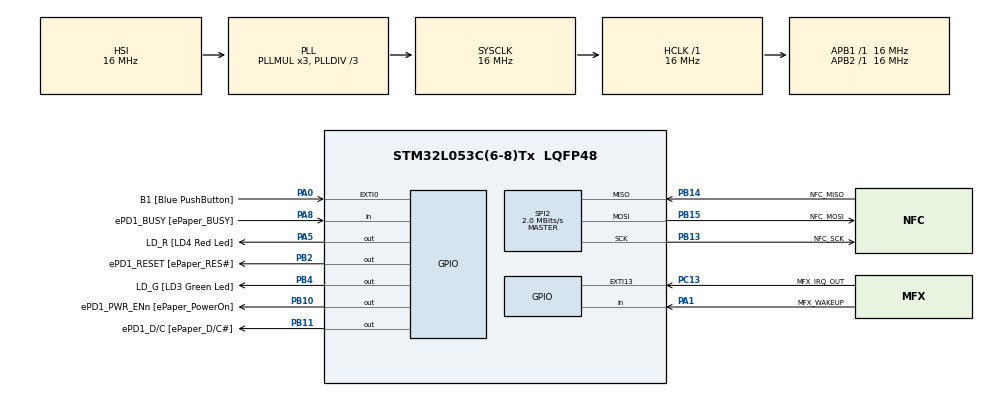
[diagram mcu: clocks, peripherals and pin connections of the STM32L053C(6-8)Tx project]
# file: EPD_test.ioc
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Mcu.Family=STM32L0
Mcu.Name=STM32L053C(6-8)Tx
Mcu.Package=LQFP48
PA0.GPIO_Label=B1 [Blue PushButton]
PA0.GPIO_ModeDefaultEXTI=GPIO_MODE_EVT_RISING
PA0.GPIO_PuPd=GPIO_NOPULL
PA0.Signal=GPXTI0
PA1.GPIO_Label=MFX_WAKEUP
PA1.Signal=GPIO_Input
PA10.GPIO_Label=USART_RX
PA10.Signal=USART1_RX
PA11.GPIO_Label=USB1_DM
PA11.Signal=USB_DM
PA12.GPIO_Label=USB1_DP
PA12.Signal=USB_DP
PA13.GPIO_Label=SWDIO
PA13.Signal=SYS_SWDIO
PA15.GPIO_Label=ePD1_CS [ePaper_CS\#]
PA15.GPIO_Mode=GPIO_MODE_AF_PP
PA15.GPIO_PuPd=GPIO_NOPULL
PA15.GPIO_Speed=GPIO_SPEED_FREQ_LOW
PA15.Signal=SPI1_NSS
PA2.Signal=TSC_G1_IO3
PA3.Signal=TSC_G1_IO4
PA5.GPIO_Label=LD_R [LD4 Red Led]
PA5.GPIO_ModeDefaultOutputPP=GPIO_MODE_OUTPUT_PP
PA5.GPIO_PuPd=GPIO_NOPULL
PA5.GPIO_Speed=GPIO_SPEED_FREQ_LOW
PA5.Signal=GPIO_Output
PA6.Signal=TSC_G2_IO3
PA7.Signal=TSC_G2_IO4
PA8.GPIO_Label=ePD1_BUSY [ePaper_BUSY]
PA8.GPIO_Mode=GPIO_MODE_INPUT
PA8.GPIO_PuPd=GPIO_NOPULL
PA8.Signal=GPIO_Input
PA9.GPIO_Label=USART_TX
PA9.Signal=USART1_TX
PB0.Signal=TSC_G3_IO2
PB1.Signal=TSC_G3_IO3
PB10.GPIO_Label=ePD1_PWR_ENn [ePaper_PowerOn]
PB10.GPIO_ModeDefaultOutputPP=GPIO_MODE_OUTPUT_PP
PB10.GPIO_PuPd=GPIO_NOPULL
PB10.GPIO_Speed=GPIO_SPEED_FREQ_LOW
PB10.Signal=GPIO_Output
PB11.GPIO_Label=ePD1_D/C [ePaper_D/C\#]
PB11.GPIO_ModeDefaultOutputPP=GPIO_MODE_OUTPUT_PP
PB11.GPIO_PuPd=GPIO_NOPULL
PB11.GPIO_Speed=GPIO_SPEED_FREQ_LOW
PB11.Signal=GPIO_Output
PB12.GPIO_Label=NFC_NSS
PB12.Signal=SPI2_NSS
PB13.GPIO_Label=NFC_SCK
PB13.Mode=Full_Duplex_Master
PB13.Signal=SPI2_SCK
PB14.GPIO_Label=NFC_MISO
PB14.Mode=Full_Duplex_Master
PB14.Signal=SPI2_MISO
PB15.GPIO_Label=NFC_MOSI
PB15.Mode=Full_Duplex_Master
PB15.Signal=SPI2_MOSI
PB2.GPIO_Label=ePD1_RESET [ePaper_RES\#]
PB2.GPIO_ModeDefaultOutputPP=GPIO_MODE_OUTPUT_PP
PB2.GPIO_PuPd=GPIO_NOPULL
PB2.GPIO_Speed=GPIO_SPEED_FREQ_LOW
PB2.Signal=GPIO_Output
PB3.GPIO_Label=ePD1_SCK [ePaper_SCK]
PB3.GPIO_Mode=GPIO_MODE_AF_PP
PB3.GPIO_PuPd=GPIO_NOPULL
PB3.GPIO_Speed=GPIO_SPEED_FREQ_LOW
PB3.Signal=SPI1_SCK
PB4.GPIO_Label=LD_G [LD3 Green Led]
PB4.GPIO_ModeDefaultOutputPP=GPIO_MODE_OUTPUT_PP
PB4.GPIO_PuPd=GPIO_NOPULL
PB4.GPIO_Speed=GPIO_SPEED_FREQ_LOW
PB4.Signal=GPIO_Output
PB5.GPIO_Label=ePD1_MOSI [ePaper_MOSI]
PB5.GPIO_Mode=GPIO_MODE_AF_PP
PB5.GPIO_PuPd=GPIO_NOPULL
PB5.GPIO_Speed=GPIO_SPEED_FREQ_LOW
PB5.Signal=SPI1_MOSI
PB8.GPIO_Label=MFX_I2C_SCL
PB8.Signal=I2C1_SCL
PB9.GPIO_Label=MFX_I2C_SDA
PB9.Signal=I2C1_SDA
PC13.GPIO_Label=MFX_IRQ_OUT
PC13.Signal=GPXTI13
PC14-OSC32_IN.GPIO_Label=PC14-OSC32_IN
PC14-OSC32_IN.Signal=RCC_OSC32_IN
PC15-OSC32_OUT.GPIO_Label=PC15-OSC32_OUT
PC15-OSC32_OUT.Signal=RCC_OSC32_OUT
PH0-OSC_IN.GPIO_Label=MCO
PH0-OSC_IN.Signal=RCC_OSC_IN
ProjectManager.HeapSize=0x200
ProjectManager.StackSize=0x400
ProjectManager.TargetToolchain=SW4STM32
RCC.AHBFreq_Value=16000000
RCC.APB1Freq_Value=16000000
RCC.APB1TimFreq_Value=16000000
RCC.APB2Freq_Value=16000000
RCC.APB2TimFreq_Value=16000000
RCC.HCLKFreq_Value=16000000
RCC.HSE_VALUE=8000000
RCC.HSI16_VALUE=16000000
RCC.HSI48MClockSelection=RCC_USBCLKSOURCE_HSI48
RCC.HSI48_VALUE=48000000
RCC.HSI_VALUE=16000000
RCC.LSE_VALUE=32768
RCC.MSI_VALUE=2097000
RCC.PLLDIV=RCC_PLLDIV_3
RCC.RTCClockSelectionVirtual=RCC_RTCCLKSOURCE_LSE
RCC.SYSCLKFreq_VALUE=16000000
RCC.SYSCLKSource=RCC_SYSCLKSOURCE_PLLCLK
RCC.VCOOutputFreq_Value=48000000
SPI2.BaudRatePrescaler=SPI_BAUDRATEPRESCALER_8
SPI2.CLKPhase=SPI_PHASE_2EDGE
SPI2.CLKPolarity=SPI_POLARITY_HIGH
SPI2.CalculateBaudRate=2.0 MBits/s
SPI2.Direction=SPI_DIRECTION_2LINES
SPI2.Mode=SPI_MODE_MASTER
SPI2.VirtualType=VM_MASTER
board=32L0538DISCOVERY

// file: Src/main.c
/**
  ******************************************************************************
  * @file           : main.c
  * @brief          : Main program body
  ******************************************************************************
  ** This notice applies to any and all portions of this file
  * that are not between comment pairs USER CODE BEGIN and
  * USER CODE END. Other portions of this file, whether
  * inserted by the user or by software development tools
  * are owned by their respective copyright owners.
  *
  * COPYRIGHT(c) 2020 STMicroelectronics
  *
  * Redistribution and use in source and binary forms, with or without modification,
  * are permitted provided that the following conditions are met:
  *   1. Redistributions of source code must retain the above copyright notice,
  *      this list of conditions and the following disclaimer.
  *   2. Redistributions in binary form must reproduce the above copyright notice,
  *      this list of conditions and the following disclaimer in the documentation
  *      and/or other materials provided with the distribution.
  *   3. Neither the name of STMicroelectronics nor the names of its contributors
  *      may be used to endorse or promote products derived from this software
  *      without specific prior written permission.
  *
  * THIS SOFTWARE IS PROVIDED BY THE COPYRIGHT HOLDERS AND CONTRIBUTORS "AS IS"
  * AND ANY EXPRESS OR IMPLIED WARRANTIES, INCLUDING, BUT NOT LIMITED TO, THE
  * IMPLIED WARRANTIES OF MERCHANTABILITY AND FITNESS FOR A PARTICULAR PURPOSE ARE
  * DISCLAIMED. IN NO EVENT SHALL THE COPYRIGHT HOLDER OR CONTRIBUTORS BE LIABLE
  * FOR ANY DIRECT, INDIRECT, INCIDENTAL, SPECIAL, EXEMPLARY, OR CONSEQUENTIAL
  * DAMAGES (INCLUDING, BUT NOT LIMITED TO, PROCUREMENT OF SUBSTITUTE GOODS OR
  * SERVICES; LOSS OF USE, DATA, OR PROFITS; OR BUSINESS INTERRUPTION) HOWEVER
  * CAUSED AND ON ANY THEORY OF LIABILITY, WHETHER IN CONTRACT, STRICT LIABILITY,
  * OR TORT (INCLUDING NEGLIGENCE OR OTHERWISE) ARISING IN ANY WAY OUT OF THE USE
  * OF THIS SOFTWARE, EVEN IF ADVISED OF THE POSSIBILITY OF SUCH DAMAGE.
  *
  ******************************************************************************
  */
#include "main.h"
#include "stm32l0xx_hal.h"
#include "spi.h"
#include "gpio.h"
#include "menu_res.c"

/* USER CODE BEGIN PV */
/* Private variables ---------------------------------------------------------*/

/* USER CODE END PV */

void SystemClock_Config(void);

/* USER CODE BEGIN PFP */
/* Private function prototypes -----------------------------------------------*/

/* USER CODE END PFP */

int main(void)
{

  /* MCU Configuration----------------------------------------------------------*/

  /* Reset of all peripherals, Initializes the Flash interface and the Systick. */
  HAL_Init();

  /* Configure the system clock */
  SystemClock_Config();

  /* Initialize all configured peripherals */
  MX_GPIO_Init();
  MX_SPI2_Init();
  /* USER CODE BEGIN 2 */
    Bsp_Init();

    //Help msg
    BSP_EPD_SetFont(&Font16);
    BSP_EPD_DisplayStringAt(0,10, (uint8_t*)"JuSt DoWnLoAd", CENTER_MODE);
    BSP_EPD_SetFont(&Font20);
    BSP_EPD_DisplayStringAt(0,5, (uint8_t*)"ThE DrIvErS", CENTER_MODE);
    BSP_EPD_SetFont(&Font8);
    BSP_EPD_DisplayStringAt(0,3, (uint8_t*)"4HEAD", CENTER_MODE);

//    BSP_EPD_SetFont(&Font16);
//    BSP_EPD_DrawImage(0, 0, 72, 172, Background_pic);
//    BSP_EPD_DisplayStringAt(0, 13, (uint8_t*)"STM32L053", RIGHT_MODE);
//    BSP_EPD_SetFont(&Font12);
//    BSP_EPD_DisplayStringAt(87, 8, (uint8_t*)"DISCOVERY", LEFT_MODE);
//    BSP_EPD_DisplayStringAt(71, 3, (uint8_t*)"DEMONSTRATION", LEFT_MODE);
//    BSP_EPD_DisplayStringAt(94, 0, (uint8_t*)"V1.0.0", LEFT_MODE);

//    BSP_EPD_DrawHLine(0,3, 90);
//
    BSP_EPD_RefreshDisplay();
//    BSP_EPD_Clear(0xff);
//
//    BSP_EPD_DrawHLine(90,14,60);
//
//    BSP_EPD_RefreshDisplay();

  /* USER CODE END 2 */

  /* Infinite loop */
  while (1)
  {

  }

}

void SystemClock_Config(void)
{

  RCC_OscInitTypeDef RCC_OscInitStruct;
  RCC_ClkInitTypeDef RCC_ClkInitStruct;

    /**Configure the main internal regulator output voltage
    */
  __HAL_PWR_VOLTAGESCALING_CONFIG(PWR_REGULATOR_VOLTAGE_SCALE1);

    /**Initializes the CPU, AHB and APB busses clocks
    */
  RCC_OscInitStruct.OscillatorType = RCC_OSCILLATORTYPE_HSI;
  RCC_OscInitStruct.HSIState = RCC_HSI_ON;
  RCC_OscInitStruct.HSICalibrationValue = 16;
  RCC_OscInitStruct.PLL.PLLState = RCC_PLL_ON;
  RCC_OscInitStruct.PLL.PLLSource = RCC_PLLSOURCE_HSI;
  RCC_OscInitStruct.PLL.PLLMUL = RCC_PLLMUL_3;
  RCC_OscInitStruct.PLL.PLLDIV = RCC_PLLDIV_3;
  if (HAL_RCC_OscConfig(&RCC_OscInitStruct) != HAL_OK)
  {
    _Error_Handler(__FILE__, __LINE__);
  }

    /**Initializes the CPU, AHB and APB busses clocks
    */
  RCC_ClkInitStruct.ClockType = RCC_CLOCKTYPE_HCLK|RCC_CLOCKTYPE_SYSCLK
                              |RCC_CLOCKTYPE_PCLK1|RCC_CLOCKTYPE_PCLK2;
  RCC_ClkInitStruct.SYSCLKSource = RCC_SYSCLKSOURCE_PLLCLK;
  RCC_ClkInitStruct.AHBCLKDivider = RCC_SYSCLK_DIV1;
  RCC_ClkInitStruct.APB1CLKDivider = RCC_HCLK_DIV1;
  RCC_ClkInitStruct.APB2CLKDivider = RCC_HCLK_DIV1;

  if (HAL_RCC_ClockConfig(&RCC_ClkInitStruct, FLASH_LATENCY_0) != HAL_OK)
  {
    _Error_Handler(__FILE__, __LINE__);
  }

    /**Configure the Systick interrupt time
    */
  HAL_SYSTICK_Config(HAL_RCC_GetHCLKFreq()/1000);

    /**Configure the Systick
    */
  HAL_SYSTICK_CLKSourceConfig(SYSTICK_CLKSOURCE_HCLK);

  /* SysTick_IRQn interrupt configuration */
  HAL_NVIC_SetPriority(SysTick_IRQn, 0, 0);
}

void _Error_Handler(char *file, int line)
{
  while(1)
  {
  }
}

/************************ (C) COPYRIGHT STMicroelectronics *****END OF FILE****/
